# cslr_ldo register map
Vendor: Texas Instruments
Peripheral module from a debugger description file (folder C5517).
Address unit: 16 bits
Registers are 16-bit, access not given, reset 0x0 unless marked. A register's access mark holds for its fields unless they carry their own. Offsets are as the file gives them; lines under a group give offsets from that group; [hi:lo] are bit positions; {n}, {i} and the like mark numbered series; 'fields as' and 'values as' point back to an identical list; <NAME> marks a mode.

## LDO — LDO Control
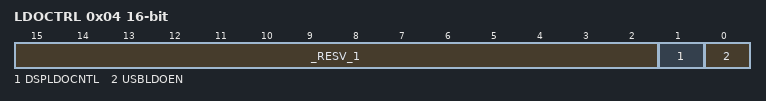
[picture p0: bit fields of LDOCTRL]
0x04 LDOCTRL — LDO enable register
  [15:2] _RESV_1 — (access N)
  [1] DSPLDOCNTL rw — Used to select the DSP LDO voltage
    0=1PT3V (DSP LDO Output Voltage is regulated to 1.3 V.); 1=1PT05V (DSP LDO Output Voltage is regulated to 1.05 V.)
  [0] USBLDOEN rw — Used to enable the USB LDO
    0=disabled (USB LDO is disabled); 1=enabled (USB LDO is enabled)
